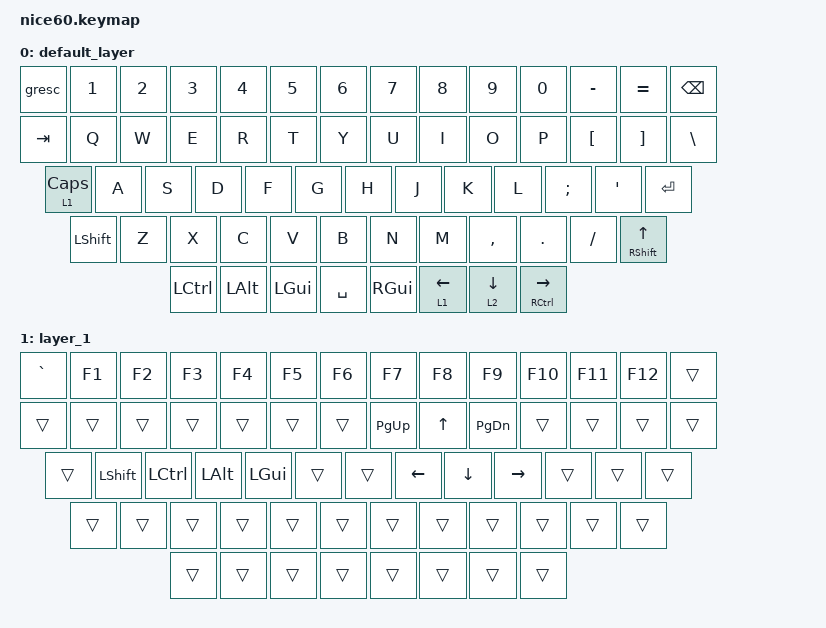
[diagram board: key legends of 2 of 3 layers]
/*
 * Copyright (c) 2021 Nick Winans
 *
 * SPDX-License-Identifier: MIT
 */

#include <behaviors.dtsi>
#include <dt-bindings/zmk/keys.h>
#include <dt-bindings/zmk/rgb.h>
#include <dt-bindings/zmk/bt.h>
#include <dt-bindings/zmk/outputs.h>
#include <dt-bindings/zmk/reset.h>
#include <dt-bindings/zmk/ext_power.h>

/ {
	keymap {
		compatible = "zmk,keymap";
		
		default_layer {
// ------------------------------------------------------------------------------------------
// | ESC |  1  |  2  |  3  |  4  |  5  |  6  |  7  |  8  |  9  |  0  |  -  |  =  |   BKSP   |
// | TAB  |  Q  |  W  |  E  |  R  |  T  |  Y  |  U  |  I  |  O  |  P  |  [  |  ]  |   "|"   |
// | CAPS  |  A  |  S  |  D  |  F  |  G  |  H  |  J  |  K  |  L  |  ;  |  '  |     ENTER    |
// |  SHIFT  |  Z  |  X  |  C  |  V  |  B  |  N  |  M  |  ,  |  .  |  /  |      SHIFT       |
// |  CTL  |  ALT  |  WIN  |            SPACE              |  WIN  |  FN1  |  FN2 |  CTL    |
// ------------------------------------------------------------------------------------------
			bindings = <
	&gresc  &kp N1 &kp N2 &kp N3 &kp N4 &kp N5 &kp N6 &kp N7 &kp N8 &kp N9 &kp N0 &kp MINUS &kp EQUAL          &kp BSPC
	&kp TAB  &kp Q  &kp W  &kp E  &kp R  &kp T  &kp Y  &kp U  &kp I  &kp O  &kp P  &kp LBKT  &kp RBKT          &kp BSLH
	&lt 1 CLCK  &kp A  &kp S  &kp D  &kp F  &kp G  &kp H  &kp J  &kp K  &kp L  &kp SEMI &kp SQT                &kp RET
	&kp LSHFT   &kp Z  &kp X  &kp C  &kp V  &kp B  &kp N  &kp M  &kp COMMA &kp DOT &kp FSLH       &mt RSHFT UP
	&kp LCTRL &kp LALT &kp LGUI             &kp SPACE                     &kp RGUI  &lt 1 LEFT &lt 2 DOWN   &mt RCTRL RIGHT
			>;
		};
		
				layer_1 {
// ------------------------------------------------------------------------------------------
// |     |     |     |     |     |     |     |     |     |     |     |     |     |          |
// |      |     |     |     |     |     |     |PG_UP| ^  |PG_DN|     |     |     |          |
// |       |SHFT | CTL | ALT | WIN |    |     | <- |  DN  |  -> |     |     |               |
// |        |     |     |     |     |     |     |     |     |     |     |                   |
// |       |       |       |                               |       |       |        |       |
// ------------------------------------------------------------------------------------------
			bindings = <
	&kp GRAVE  &kp F1 &kp F2 &kp F3 &kp F4 &kp F5 &kp F6 &kp F7 &kp F8 &kp F9 &kp F10 &kp F11 &kp F12  &trans
	&trans  &trans  &trans  &trans  &trans  &trans  &trans  &kp PG_UP  &kp UP  &kp PG_DN  &trans  &trans  &trans  &trans
	&trans  &kp LSHFT  &kp LCTRL  &kp LALT  &kp LGUI  &trans  &trans  &kp LEFT  &kp DOWN  &kp RIGHT  &trans &trans           &trans
	&trans   &trans  &trans  &trans  &trans  &trans  &trans  &trans  &trans &trans &trans           &trans
	&trans &trans &trans             &trans                     &trans  &trans  &trans   &trans
			>;
		};

		layer_2 {
// ------------------------------------------------------------------------------------------------
// | BT CLR | BT 1  | BT 2  | BT 3  | BT 4  | F5  | F6  | F7  | F8  | F9  | F10  | F11 | F12 | EFFECT REV |
// |         |   |  UP |   | HUEUP | SATUP | BRIUP | SPDUP |   |     |    |     |     |           |
// |          | LT |  DN  | RT | HUEDN | SATDN | BRIDN | SPDDN |   |     |   |     |  EFFECT FORW |
// |             |     |      |      |     |     |     |     |     |     |     |                  |
// |         |      |      |             TOG RGB                | PRT SCR |       |       |  DEL  |
// ------------------------------------------------------------------------------------------------
			bindings = <
	&bt BT_CLR   &bt BT_SEL 0    &bt BT_SEL 1    &bt BT_SEL 2  &bt BT_SEL 3           &trans          &trans          &trans          &trans   &trans   &trans  &trans &trans  &trans 
	&trans  &trans    &trans    &trans  &trans  &trans &trans &trans  &trans   &trans   &trans   &trans  &trans          &trans 
	&trans   &trans  &trans  &trans &trans &trans &trans &trans &trans &trans   &trans   &trans   &trans        &trans
	&trans    &trans    &trans    &trans   &trans          &trans          &trans          &trans          &trans   &trans   &trans                          &trans
	&trans  &trans   &trans                            &trans                                      &trans      &trans      &trans               &trans
			>;
		};
	};
};
